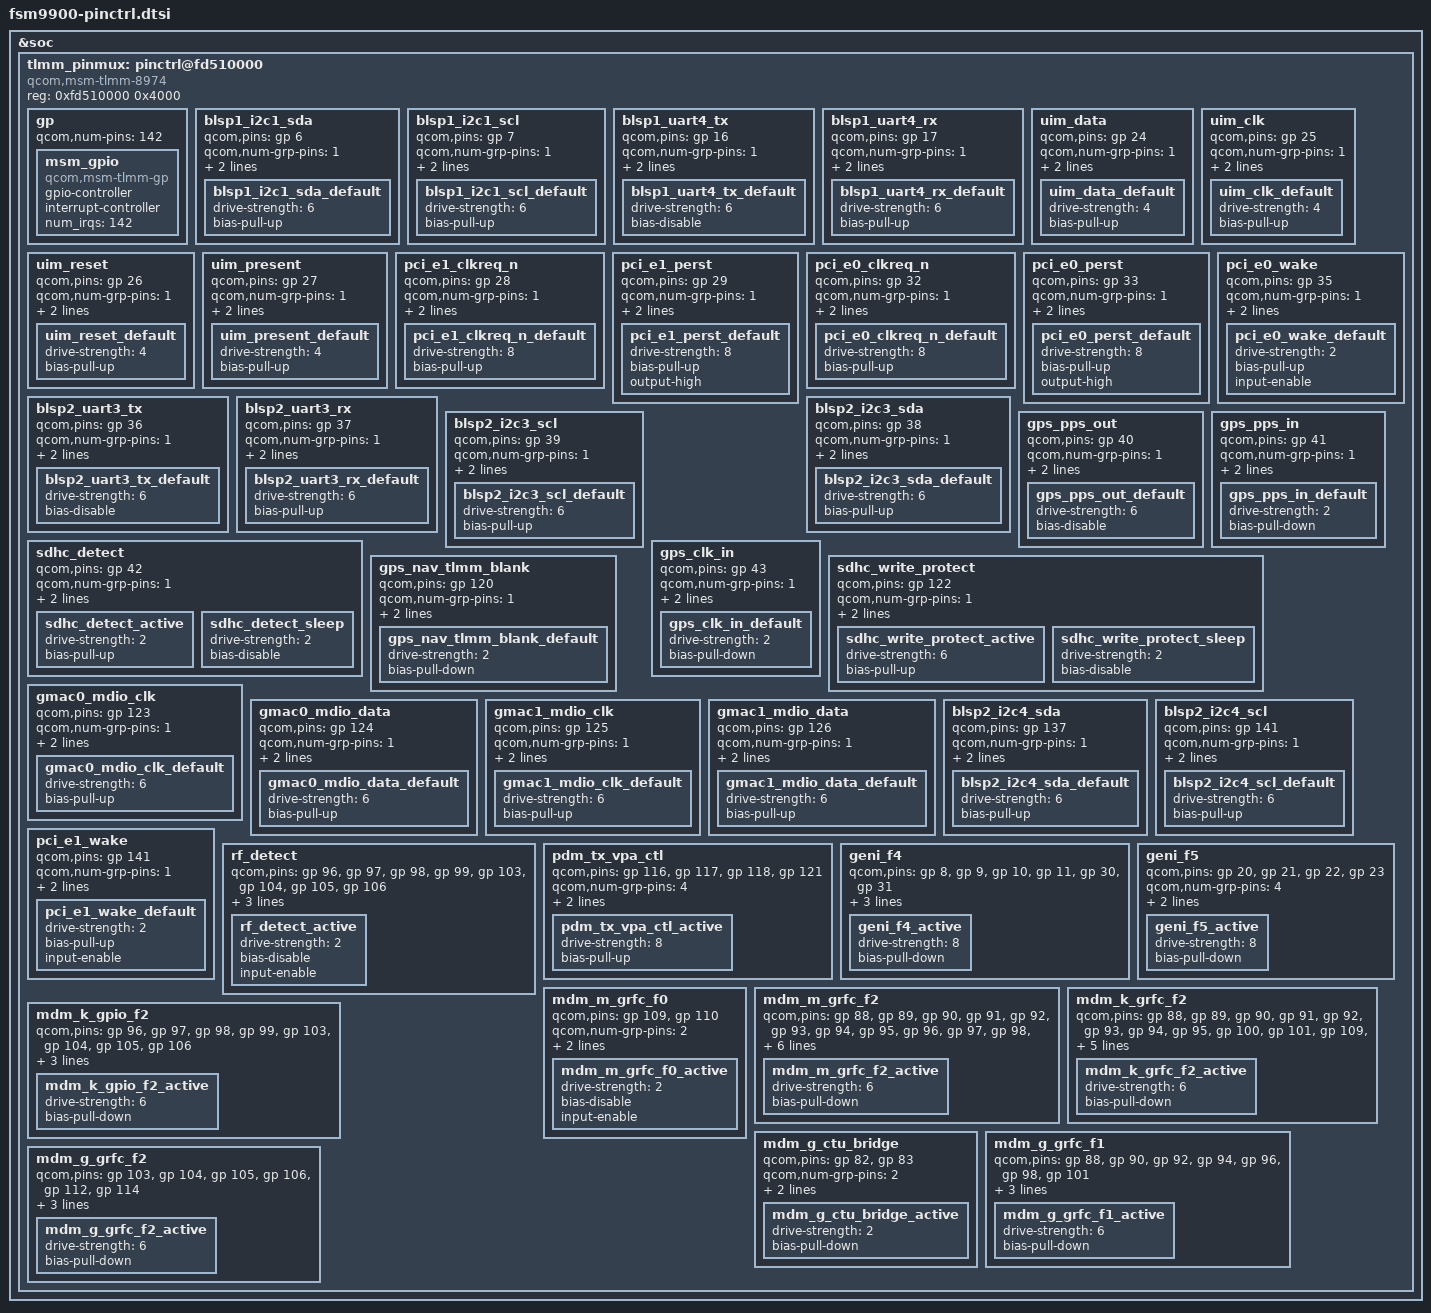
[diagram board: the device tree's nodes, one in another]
/* Copyright (c) 2015-2016, The Linux Foundation. All rights reserved.
 *
 * This program is free software; you can redistribute it and/or modify
 * it under the terms of the GNU General Public License version 2 and
 * only version 2 as published by the Free Software Foundation.
 *
 * This program is distributed in the hope that it will be useful,
 * but WITHOUT ANY WARRANTY; without even the implied warranty of
 * MERCHANTABILITY or FITNESS FOR A PARTICULAR PURPOSE.  See the
 * GNU General Public License for more details.
 */

&soc {
	tlmm_pinmux: pinctrl@fd510000 {
		compatible = "qcom,msm-tlmm-8974";
		reg = <0xfd510000 0x4000>;

		/* General purpose pins */
		gp: gp {
			#qcom,pin-cells = <1>;
			qcom,num-pins = <142>;
			msm_gpio: msm_gpio {
				compatible = "qcom,msm-tlmm-gp";
				gpio-controller;
				#gpio-cells = <2>;
				interrupt-controller;
				#interrupt-cells = <2>;
				num_irqs = <142>;
			};
		};

		blsp1_i2c1_sda {
			qcom,pins = <&gp 6>;
			qcom,num-grp-pins = <1>;
			label = "blsp1_i2c1_sda";
			qcom,pin-func = <3>;
			blsp1_i2c1_sda_default: blsp1_i2c1_sda_default {
				drive-strength = <6>;
				bias-pull-up;
			};
		};

		blsp1_i2c1_scl {
			qcom,pins = <&gp 7>;
			qcom,num-grp-pins = <1>;
			label = "blsp1_i2c1_scl";
			qcom,pin-func = <3>;
			blsp1_i2c1_scl_default: blsp1_i2c1_scl_default {
				drive-strength = <6>;
				bias-pull-up;
			};
		};

		blsp1_uart4_tx {
			qcom,pins = <&gp 16>;
			qcom,num-grp-pins = <1>;
			label = "blsp1_uart4_tx";
			qcom,pin-func = <2>;
			blsp1_uart4_tx_default: blsp1_uart4_tx_default {
				drive-strength = <6>;
				bias-disable;
			};
		};

		blsp1_uart4_rx {
			qcom,pins = <&gp 17>;
			qcom,num-grp-pins = <1>;
			label = "blsp1_uart4_rx";
			qcom,pin-func = <2>;
			blsp1_uart4_rx_default: blsp1_uart4_rx_default {
				drive-strength = <6>;
				bias-pull-up;
			};
		};

		uim_data {
			qcom,pins = <&gp 24>;
			qcom,num-grp-pins = <1>;
			label = "uim_data";
			qcom,pin-func = <1>;
			uim_data_default: uim_data_default {
				drive-strength = <4>;
				bias-pull-up;
			};
		};

		uim_clk {
			qcom,pins = <&gp 25>;
			qcom,num-grp-pins = <1>;
			label = "uim_clk";
			qcom,pin-func = <1>;
			uim_clk_default: uim_clk_default {
				drive-strength = <4>;
				bias-pull-up;
			};
		};

		uim_reset {
			qcom,pins = <&gp 26>;
			qcom,num-grp-pins = <1>;
			label = "uim_reset";
			qcom,pin-func = <1>;
			uim_reset_default: uim_reset_default {
				drive-strength = <4>;
				bias-pull-up;
			};
		};

		uim_present {
			qcom,pins = <&gp 27>;
			qcom,num-grp-pins = <1>;
			label = "uim_present";
			qcom,pin-func = <1>;
			uim_present_default: uim_present_default {
				drive-strength = <4>;
				bias-pull-up;
			};
		};

		pci_e1_clkreq_n {
			qcom,pins = <&gp 28>;
			qcom,num-grp-pins = <1>;
			label = "pci_e1_clkreq_n";
			qcom,pin-func = <4>;
			pci_e1_clkreq_n_default: pci_e1_clkreq_n_default {
				drive-strength = <8>;
				bias-pull-up;
			};
		};

		pci_e1_perst {
			qcom,pins = <&gp 29>;
			qcom,num-grp-pins = <1>;
			label = "pci_e1_perst";
			qcom,pin-func = <0>; /* GPIO */
			pci_e1_perst_default: pci_e1_perst_default {
				drive-strength = <8>;
				bias-pull-up;
				output-high;
			};
		};

		pci_e0_clkreq_n {
			qcom,pins = <&gp 32>;
			qcom,num-grp-pins = <1>;
			label = "pci_e0_clkreq_n";
			qcom,pin-func = <4>;
			pci_e0_clkreq_n_default: pci_e0_clkreq_n_default {
				drive-strength = <8>;
				bias-pull-up;
			};
		};

		pci_e0_perst {
			qcom,pins = <&gp 33>;
			qcom,num-grp-pins = <1>;
			label = "pci_e0_perst";
			qcom,pin-func = <0>; /* GPIO */
			pci_e0_perst_default: pci_e0_perst_default {
				drive-strength = <8>;
				bias-pull-up;
				output-high;
			};
		};

		pci_e0_wake {
			qcom,pins = <&gp 35>;
			qcom,num-grp-pins = <1>;
			label = "pci_e0_wake";
			qcom,pin-func = <0>; /* GPIO */
			pci_e0_wake_default: pci_e0_wake_default {
				drive-strength = <2>;
				bias-pull-up;
				input-enable;
			};
		};

		blsp2_uart3_tx {
			qcom,pins = <&gp 36>;
			qcom,num-grp-pins = <1>;
			label = "blsp2_uart3_tx";
			qcom,pin-func = <2>;
			blsp2_uart3_tx_default: blsp2_uart3_tx_default {
				drive-strength = <6>;
				bias-disable;
			};
		};

		blsp2_uart3_rx {
			qcom,pins = <&gp 37>;
			qcom,num-grp-pins = <1>;
			label = "blsp2_uart3_rx";
			qcom,pin-func = <2>;
			blsp2_uart3_rx_default: blsp2_uart3_rx_default {
				drive-strength = <6>;
				bias-pull-up;
			};
		};

		blsp2_i2c3_sda {
			qcom,pins = <&gp 38>;
			qcom,num-grp-pins = <1>;
			label = "blsp2_i2c3_sda";
			qcom,pin-func = <3>;
			blsp2_i2c3_sda_default: blsp2_i2c3_sda_default {
				drive-strength = <6>;
				bias-pull-up;
			};
		};

		blsp2_i2c3_scl {
			qcom,pins = <&gp 39>;
			qcom,num-grp-pins = <1>;
			label = "blsp2_i2c3_scl";
			qcom,pin-func = <3>;
			blsp2_i2c3_scl_default: blsp2_i2c3_scl_default {
				drive-strength = <6>;
				bias-pull-up;
			};
		};

		gps_pps_out {
			qcom,pins = <&gp 40>;
			qcom,num-grp-pins = <1>;
			label = "gps_pps_out";
			qcom,pin-func = <1>;
			gps_pps_out_default: gps_pps_out_default {
				drive-strength = <6>;
				bias-disable;
			};
		};

		gps_pps_in {
			qcom,pins = <&gp 41>;
			qcom,num-grp-pins = <1>;
			label = "gps_pps_in";
			qcom,pin-func = <1>;
			gps_pps_in_default: gps_pps_in_default {
				drive-strength = <2>;
				bias-pull-down;
			};
		};

		sdhc_detect {
			qcom,pins = <&gp 42>;
			qcom,num-grp-pins = <1>;
			label = "sdhc_detect";
			qcom,pin-func = <0>; /* GPIO */
			sdhc_detect_active: sdhc_detect_active {
				drive-strength = <2>;
				bias-pull-up;
			};
			sdhc_detect_sleep: sdhc_detect_sleep {
				drive-strength = <2>;
				bias-disable;
			};
		};

		gps_clk_in {
			qcom,pins = <&gp 43>;
			qcom,num-grp-pins = <1>;
			label = "gps_clk_in";
			qcom,pin-func = <1>;
			gps_clk_in_default: gps_clk_in_default {
				drive-strength = <2>;
				bias-pull-down;
			};
		};

		gps_nav_tlmm_blank {
			qcom,pins = <&gp 120>;
			qcom,num-grp-pins = <1>;
			label = "gps_nav_tlmm_blank";
			qcom,pin-func = <2>;
			gps_nav_tlmm_blank_default: gps_nav_tlmm_blank_default {
				drive-strength = <2>;
				bias-pull-down;
			};
		};

		sdhc_write_protect {
			qcom,pins = <&gp 122>;
			qcom,num-grp-pins = <1>;
			label = "sdhc_write_protect";
			qcom,pin-func = <0>; /* GPIO */
			sdhc_write_protect_active: sdhc_write_protect_active {
				drive-strength = <6>;
				bias-pull-up;
			};
			sdhc_write_protect_sleep: sdhc_write_protect_sleep {
				drive-strength = <2>;
				bias-disable;
			};
		};

		gmac0_mdio_clk {
			qcom,pins = <&gp 123>;
			qcom,num-grp-pins = <1>;
			label = "gmac0_mdio_clk";
			qcom,pin-func = <1>;
			gmac0_mdio_clk_default: gmac0_mdio_clk_default {
				drive-strength = <6>;
				bias-pull-up;
			};
		};

		gmac0_mdio_data {
			qcom,pins = <&gp 124>;
			qcom,num-grp-pins = <1>;
			label = "gmac0_mdio_data";
			qcom,pin-func = <1>;
			gmac0_mdio_data_default: gmac0_mdio_data_default {
				drive-strength = <6>;
				bias-pull-up;
			};
		};

		gmac1_mdio_clk {
			qcom,pins = <&gp 125>;
			qcom,num-grp-pins = <1>;
			label = "gmac1_mdio_clk";
			qcom,pin-func = <1>;
			gmac1_mdio_clk_default: gmac1_mdio_clk_default {
				drive-strength = <6>;
				bias-pull-up;
			};
		};

		gmac1_mdio_data {
			qcom,pins = <&gp 126>;
			qcom,num-grp-pins = <1>;
			label = "gmac1_mdio_data";
			qcom,pin-func = <1>;
			gmac1_mdio_data_default: gmac1_mdio_data_default {
				drive-strength = <6>;
				bias-pull-up;
			};
		};

		blsp2_i2c4_sda {
			qcom,pins = <&gp 137>;
			qcom,num-grp-pins = <1>;
			label = "blsp2_i2c4_sda";
			qcom,pin-func = <5>;
			blsp2_i2c4_sda_default: blsp2_i2c4_sda_default {
				drive-strength = <6>;
				bias-pull-up;
			};
		};

		blsp2_i2c4_scl {
			qcom,pins = <&gp 141>;
			qcom,num-grp-pins = <1>;
			label = "blsp2_i2c4_scl";
			qcom,pin-func = <5>;
			blsp2_i2c4_scl_default: blsp2_i2c4_scl_default {
				drive-strength = <6>;
				bias-pull-up;
			};
		};

		pci_e1_wake {
			qcom,pins = <&gp 141>;
			qcom,num-grp-pins = <1>;
			label = "pci_e1_wake";
			qcom,pin-func = <0>; /* GPIO */
			pci_e1_wake_default: pci_e1_wake_default {
				drive-strength = <2>;
				bias-pull-up;
				input-enable;
			};
		};

		/*
		 *  Pins for RF operation
		 */

		rf_detect {
			qcom,pins =
				<&gp 96>,  /* FTR2_HB_NL_SEL */
				<&gp 97>,  /* FTR2_LB_NL_SEL */
				<&gp 98>,  /* FTR1_HB_NL_SEL */
				<&gp 99>,  /* FTR1_LB_NL_SEL */
				<&gp 103>, /* FTR1_SBI_SEL0  */
				<&gp 104>, /* FTR1_SBI_SEL1  */
				<&gp 105>, /* FTR2_SBI_SEL0  */
				<&gp 106>; /* FTR2_SBI_SEL1  */
			qcom,num-grp-pins = <8>;
			label = "rf_detect";
			qcom,pin-func = <0>; /* GPIO */
			rf_detect_active: rf_detect_active {
				drive-strength = <2>;
				bias-disable;
				input-enable;
			};
		};

		pdm_tx_vpa_ctl {
			qcom,pins =
				<&gp 116>, /* TX1_VPA_CTL */
				<&gp 117>, /* TX2_VPA_CTL */
				<&gp 118>, /* TX3_VPA_CTL */
				<&gp 121>; /* TX4_VPA_CTL */
			qcom,num-grp-pins = <4>;
			label = "pdm_tx_vpa_ctl";
			qcom,pin-func = <1>;
			pdm_tx_vpa_ctl_active: pdm_tx_vpa_ctl_active {
				drive-strength = <8>;
				bias-pull-up;
			};
		};

		geni_f4 {
			qcom,pins =
				<&gp 8>,  /* GENI7 DATA */
				<&gp 9>,  /* GENI1 DATA */
				<&gp 10>, /* GENI2 DATA */
				<&gp 11>, /* GENI7 CLK  */
				<&gp 30>, /* GENI5 DATA */
				<&gp 31>; /* GENI5 CLK  */
			qcom,num-grp-pins = <6>;
			label = "geni_f4";
			qcom,pin-func = <4>;
			geni_f4_active: geni_f4_active {
				drive-strength = <8>;
				bias-pull-down;
			};
		};

		geni_f5 {
			qcom,pins =
				<&gp 20>, /* GENI3 DATA */
				<&gp 21>, /* GENI4 DATA */
				<&gp 22>, /* GENI6 DATA */
				<&gp 23>; /* GENI6 CLK  */
			qcom,num-grp-pins = <4>;
			label = "geni_f5";
			qcom,pin-func = <5>;
			geni_f5_active: geni_f5_active {
				drive-strength = <8>;
				bias-pull-down;
			};
		};

		/* MDM GRFC Pins for RF boards mdm_m, mdm_k and mdm_g */

		mdm_m_grfc_f0 {
			qcom,pins =
				<&gp 109>, /* WTR1605_RX_ON / FTR1_INTERRUPT */
				<&gp 110>; /* WTR1605_RF_ON / FTR2_INTERRUPT */
			qcom,num-grp-pins = <2>;
			qcom,pin-func = <0>; /* GPIO */
			label = "mdm_m_grfc_f0";
			mdm_m_grfc_f0_active: mdm_m_grfc_f0_active {
				drive-strength = <2>;
				bias-disable;
				input-enable;
			};
		};

		mdm_m_grfc_f2 {
			qcom,pins =
				<&gp 88>,  /* TX1_HB_PA_EN / TX1_PA_EN            */
				<&gp 89>,  /* TX1_LB_PA_EN / TX2_PA_EN            */
				<&gp 90>,  /* TX2_HB_PA_EN / FTR1_DPD_SEL1        */
				<&gp 91>,  /* TX2_LB_PA_EN / FTR1_DPD_SEL0        */
				<&gp 92>,  /* TX3_HB_PA_EN / TX3_PA_EN            */
				<&gp 93>,  /* TX3_LB_PA_EN / TX4_PA_EN            */
				<&gp 94>,  /* TX4_HB_PA_EN / FTR2_DPD_SEL1        */
				<&gp 95>,  /* TX4_LB_PA_EN / FTR2_DPD_SEL0        */
				<&gp 96>,  /* TX3_TX4_HB_PA_EN / FTR2_NL_SW1_SEL  */
				<&gp 97>,  /* TX3_TX4_LB_PA_EN / FTR2_NL_SW2_SEL  */
				<&gp 98>,  /* TX1_TX2_HB_PA_EN / FTR1_NL_SW1_SEL  */
				<&gp 99>,  /* TX1_TX2_LB_PA_EN / FTR1_NL_SW2_SEL  */
				<&gp 100>, /* ANT1_HBLB_FTR_SEL / SPARE           */
				<&gp 101>, /* FTR2_TXRX_SW_SEL                    */
				<&gp 102>, /* FTR1_TXRX_SW_SEL                    */
				<&gp 103>, /* HB_TDD / FTR1_RX_ON                 */
				<&gp 104>, /* SPARE                               */
				<&gp 105>, /* FTR2_SEL0 / FTR2_RX_ON              */
				<&gp 106>, /* SPARE                               */
				<&gp 111>, /* WTR2605_RX_ON / SPARE               */
				<&gp 112>, /* TX1_VPA_EN                          */
				<&gp 113>, /* TX2_VPA_EN                          */
				<&gp 114>, /* TX3_VPA_EN                          */
				<&gp 115>; /* TX4_VPA_EN                          */
			qcom,num-grp-pins = <24>;
			qcom,pin-func = <2>;
			label = "mdm_m_grfc_f2";
			mdm_m_grfc_f2_active: mdm_m_grfc_f2_active {
				drive-strength = <6>;
				bias-pull-down;
			};
		};

		mdm_k_grfc_f2 {
			qcom,pins =
				<&gp 88>,  /* TX1_HB_PA_EN / TX1_PA_EN       */
				<&gp 89>,  /* TX1_LB_PA_EN / TX2_PA_EN       */
				<&gp 90>,  /* TX2_HB_PA_EN / FTR1_DPD_SEL0   */
				<&gp 91>,  /* TX2_LB_PA_EN / FTR1_DPD_SEL1   */
				<&gp 92>,  /* TX3_HB_PA_EN / TX3_PA_EN       */
				<&gp 93>,  /* TX3_LB_PA_EN / TX4_PA_EN       */
				<&gp 94>,  /* TX4_HB_PA_EN / FTR2_DPD_SEL0   */
				<&gp 95>,  /* TX4_LB_PA_EN / FTR2_DPD_SEL1   */
				<&gp 100>, /* ANT1_HBLB_FTR_SEL / SPARE      */
				<&gp 101>, /* HB_HDD / SPARE                 */
				<&gp 109>, /* WTR1605_RX_ON / FTR1_INTERRUPT */
				<&gp 110>, /* WTR1605_RF_ON / FTR2_INTERRUPT */
				<&gp 111>, /* WTR2605_RX_ON / SPARE          */
				<&gp 112>, /* TX1_VPA_EN                     */
				<&gp 113>, /* TX2_VPA_EN                     */
				<&gp 114>, /* TX3_VPA_EN                     */
				<&gp 115>; /* TX4_VPA_EN                     */
			qcom,num-grp-pins = <17>;
			qcom,pin-func = <2>;
			label = "mdm_k_grfc_f2";
			mdm_k_grfc_f2_active: mdm_k_grfc_f2_active {
				drive-strength = <6>;
				bias-pull-down;
			};
		};

		mdm_k_gpio_f2 {
			qcom,pins =
				<&gp 96>,  /* TX3_TX4_HB_PA_EN / FTR1_NL_SW1_SEL  */
				<&gp 97>,  /* TX3_TX4_LB_PA_EN / FTR1_NL_SW2_SEL  */
				<&gp 98>,  /* TX1_TX2_HB_PA_EN / FTR2_NL_SW1_SEL  */
				<&gp 99>,  /* TX1_TX2_LB_PA_EN / FTR2_NL_SW2_SEL  */
				<&gp 103>, /* FTR1_SEL0 / FTR2_TXRX_SW_SEL        */
				<&gp 104>, /* FTR1_SEL1 / FTR1_TXRX_SW_SEL        */
				<&gp 105>, /* FTR2_SEL0 / FTR1_RX_ON              */
				<&gp 106>; /* FTR2_SEL1 / FTR1_DPD_ON             */
			qcom,num-grp-pins = <8>;
			qcom,pin-func = <2>;
			label = "mdm_k_gpio_f2";
			mdm_k_gpio_f2_active: mdm_k_gpio_f2_active {
				drive-strength = <6>;
				bias-pull-down;
			};
		};

		mdm_g_ctu_bridge {
			qcom,pins =
				<&gp 82>, /* CTU_GPIO_BRIDGE[48] */
				<&gp 83>; /* CTU_GPIO_BRIDGE[47] */
			qcom,num-grp-pins = <2>;
			qcom,pin-func = <2>;
			label = "mdm_g_ctu_bridge";
			mdm_g_ctu_bridge_active: mdm_g_ctu_bridge_active {
				drive-strength = <2>;
				bias-pull-down;
			};
		};

		mdm_g_grfc_f1 {
			qcom,pins =
				<&gp 88>,  /* TX1_HB_PA_EN / TX1_PA_EN      */
				<&gp 90>,  /* TX2_HB_PA_EN / FTR1_DPD_SEL0  */
				<&gp 92>,  /* TX2_LB_PA_EN / FTR1_DPD_SEL1  */
				<&gp 94>,  /* TX3_HB_PA_EN / TX3_PA_EN      */
				<&gp 96>,  /* TX3_LB_PA_EN / TX4_PA_EN      */
				<&gp 98>,  /* TX4_HB_PA_EN / FTR2_DPD_SEL0  */
				<&gp 101>; /* HB_HDD / SPARE                */
			qcom,num-grp-pins = <7>;
			qcom,pin-func = <1>;
			label = "mdm_g_grfc_f1";
			mdm_g_grfc_f1_active: mdm_g_grfc_f1_active {
				drive-strength = <6>;
				bias-pull-down;
			};
		};

		mdm_g_grfc_f2 {
			qcom,pins =
				<&gp 103>, /* FTR1_SEL0 / FTR2_TXRX_SW_SEL */
				<&gp 104>, /* FTR1_SEL1 / FTR1_TXRX_SW_SEL */
				<&gp 105>, /* FTR2_SEL0 / FTR1_RX_ON       */
				<&gp 106>, /* FTR2_SEL1 / FTR1_DPD_ON      */
				<&gp 112>, /* TX1_VPA_EN                   */
				<&gp 114>; /* TX1_VPA_EN                   */
			qcom,num-grp-pins = <6>;
			qcom,pin-func = <2>;
			label = "mdm_g_grfc_f2";
			mdm_g_grfc_f2_active: mdm_g_grfc_f2_active {
				drive-strength = <6>;
				bias-pull-down;
			};
		};
	};
};
